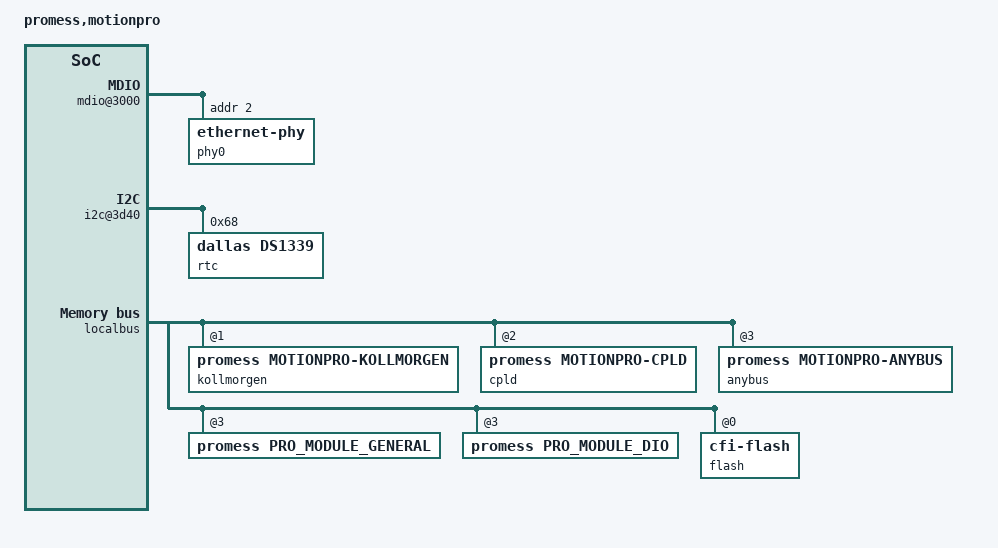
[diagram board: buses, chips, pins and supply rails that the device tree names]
/include/ "mpc5200b.dtsi"
&gpt0 { fsl,has-wdt; };
&gpt6 {  
	compatible = "promess,motionpro-led";
	label = "motionpro-statusled";
	blink-delay = <100>;  
};
&gpt7 {  
	compatible = "promess,motionpro-led";
	label = "motionpro-readyled";
};
/ {
	model = "promess,motionpro";
	compatible = "promess,motionpro";
	soc5200@f0000000 {
		can@900 {
			status = "disabled";
		};
		psc@2000 {		 
			compatible = "fsl,mpc5200b-psc-uart","fsl,mpc5200-psc-uart";
		};
		psc@2200 {		 
			compatible = "fsl,mpc5200b-psc-spi","fsl,mpc5200-psc-spi";
			cell-index = <1>;
		};
		psc@2400 {		 
			status = "disabled";
		};
		psc@2600 {		 
			status = "disabled";
		};
		psc@2800 {		 
			compatible = "fsl,mpc5200b-psc-uart","fsl,mpc5200-psc-uart";
		};
		psc@2c00 {		 
			status = "disabled";
		};
		ethernet@3000 {
			phy-handle = <&phy0>;
		};
		mdio@3000 {
			phy0: ethernet-phy@2 {
				reg = <2>;
			};
		};
		i2c@3d00 {
			status = "disabled";
		};
		i2c@3d40 {
			rtc@68 {
				compatible = "dallas,ds1339";
				reg = <0x68>;
			};
		};
		sram@8000 {
			compatible = "fsl,mpc5200b-sram","fsl,mpc5200-sram";
			reg = <0x8000 0x4000>;
		};
	};
	pci@f0000d00 {
		status = "disabled";
	};
	localbus {
		ranges = <0 0 0xff000000 0x01000000
			  1 0 0x50000000 0x00010000
			  2 0 0x50010000 0x00010000
			  3 0 0x50020000 0x00010000>;
		kollmorgen@1,0 {
			compatible = "promess,motionpro-kollmorgen";
			reg = <1 0 0x10000>;
			interrupts = <1 1 0>;
		};
		cpld@2,0 {
			compatible = "promess,motionpro-cpld";
			reg = <2 0 0x10000>;
		};
		anybus@3,0 {
			compatible = "promess,motionpro-anybus";
			reg = <3 0 0x10000>;
		};
		pro_module_general@3,0 {
			compatible = "promess,pro_module_general";
			reg = <3 0 3>;
		};
		pro_module_dio@3,800 {
			compatible = "promess,pro_module_dio";
			reg = <3 0x800 2>;
		};
		flash@0,0 {
			compatible = "cfi-flash";
			reg = <0 0 0x01000000>;
			bank-width = <2>;
			device-width = <2>;
			#size-cells = <1>;
			#address-cells = <1>;
		};
	};
};
